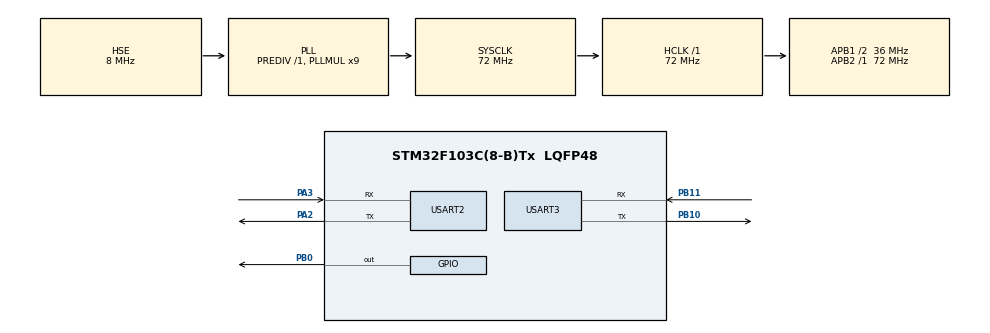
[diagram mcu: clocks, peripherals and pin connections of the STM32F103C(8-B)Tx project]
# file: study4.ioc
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FREERTOS.Tasks01=motorcontrol,40,512,Motorcontrol,Default,NULL,Dynamic,NULL,NULL;motorfeedback,24,512,Motorfeedback,Default,NULL,Dynamic,NULL,NULL
FREERTOS.configTOTAL_HEAP_SIZE=10240
Mcu.Family=STM32F1
Mcu.Name=STM32F103C(8-B)Tx
Mcu.Package=LQFP48
NVIC.PriorityGroup=NVIC_PRIORITYGROUP_4
NVIC.TIM3_IRQn=true\:15\:0\:false\:false\:true\:false\:false\:true\:true
NVIC.TimeBase=TIM3_IRQn
NVIC.TimeBaseIP=TIM3
NVIC.USART2_IRQn=true\:5\:0\:false\:false\:true\:true\:true\:true\:true
NVIC.USART3_IRQn=false\:5\:0\:false\:false\:true\:true\:false\:true\:true
PA13.Mode=Serial_Wire
PA13.Signal=SYS_JTMS-SWDIO
PA14.Mode=Serial_Wire
PA14.Signal=SYS_JTCK-SWCLK
PA2.Mode=Asynchronous
PA2.Signal=USART2_TX
PA3.Mode=Asynchronous
PA3.Signal=USART2_RX
PB0.Signal=GPIO_Output
PB10.Mode=Asynchronous
PB10.Signal=USART3_TX
PB11.Mode=Asynchronous
PB11.Signal=USART3_RX
PD0-OSC_IN.Mode=HSE-External-Oscillator
PD0-OSC_IN.Signal=RCC_OSC_IN
PD1-OSC_OUT.Mode=HSE-External-Oscillator
PD1-OSC_OUT.Signal=RCC_OSC_OUT
ProjectManager.HeapSize=0x200
ProjectManager.StackSize=0x400
ProjectManager.TargetToolchain=CMake
RCC.AHBFreq_Value=72000000
RCC.APB1CLKDivider=RCC_HCLK_DIV2
RCC.APB1Freq_Value=36000000
RCC.APB1TimFreq_Value=72000000
RCC.APB2Freq_Value=72000000
RCC.APB2TimFreq_Value=72000000
RCC.HCLKFreq_Value=72000000
RCC.PLLMUL=RCC_PLL_MUL9
RCC.PLLSourceVirtual=RCC_PLLSOURCE_HSE
RCC.SYSCLKFreq_VALUE=72000000
RCC.SYSCLKSource=RCC_SYSCLKSOURCE_PLLCLK
RCC.USBFreq_Value=72000000
USART2.VirtualMode=VM_ASYNC
USART3.VirtualMode=VM_ASYNC
VP_FREERTOS_VS_CMSIS_V2.Mode=CMSIS_V2
VP_SYS_VS_tim3.Mode=TIM3
board=custom

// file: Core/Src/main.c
/* USER CODE BEGIN Header */
/**
  ******************************************************************************
  * @file           : main.c
  * @brief          : Main program body
  ******************************************************************************
  * @attention
  *
  * Copyright (c) 2026 STMicroelectronics.
  * All rights reserved.
  *
  * This software is licensed under terms that can be found in the LICENSE file
  * in the root directory of this software component.
  * If no LICENSE file comes with this software, it is provided AS-IS.
  *
  ******************************************************************************
  */
/* USER CODE END Header */
#include "main.h"
#include "cmsis_os.h"
#include "usart.h"
#include "gpio.h"

void SystemClock_Config(void);
void MX_FREERTOS_Init(void);

/* USER CODE BEGIN 0 */
volatile uint8_t g_uart2_flag = 0;
volatile uint8_t g_uart2_data = 0;
/* USER CODE END 0 */

int main(void)
{

  /* MCU Configuration--------------------------------------------------------*/

  /* Reset of all peripherals, Initializes the Flash interface and the Systick. */
  HAL_Init();

  /* Configure the system clock */
  SystemClock_Config();

  /* Initialize all configured peripherals */
  MX_GPIO_Init();
  MX_USART3_UART_Init();
  MX_USART2_UART_Init();

  /* Init scheduler */
  osKernelInitialize();  /* Call init function for freertos objects (in cmsis_os2.c) */
  MX_FREERTOS_Init();

  /* Start scheduler */
  osKernelStart();

  /* We should never get here as control is now taken by the scheduler */

  /* Infinite loop */
  while (1)
  {

  }
}

void SystemClock_Config(void)
{
  RCC_OscInitTypeDef RCC_OscInitStruct = {0};
  RCC_ClkInitTypeDef RCC_ClkInitStruct = {0};

  /** Initializes the RCC Oscillators according to the specified parameters
  * in the RCC_OscInitTypeDef structure.
  */
  RCC_OscInitStruct.OscillatorType = RCC_OSCILLATORTYPE_HSE;
  RCC_OscInitStruct.HSEState = RCC_HSE_ON;
  RCC_OscInitStruct.HSEPredivValue = RCC_HSE_PREDIV_DIV1;
  RCC_OscInitStruct.HSIState = RCC_HSI_ON;
  RCC_OscInitStruct.PLL.PLLState = RCC_PLL_ON;
  RCC_OscInitStruct.PLL.PLLSource = RCC_PLLSOURCE_HSE;
  RCC_OscInitStruct.PLL.PLLMUL = RCC_PLL_MUL9;
  if (HAL_RCC_OscConfig(&RCC_OscInitStruct) != HAL_OK)
  {
    Error_Handler();
  }

  /** Initializes the CPU, AHB and APB buses clocks
  */
  RCC_ClkInitStruct.ClockType = RCC_CLOCKTYPE_HCLK|RCC_CLOCKTYPE_SYSCLK
                              |RCC_CLOCKTYPE_PCLK1|RCC_CLOCKTYPE_PCLK2;
  RCC_ClkInitStruct.SYSCLKSource = RCC_SYSCLKSOURCE_PLLCLK;
  RCC_ClkInitStruct.AHBCLKDivider = RCC_SYSCLK_DIV1;
  RCC_ClkInitStruct.APB1CLKDivider = RCC_HCLK_DIV2;
  RCC_ClkInitStruct.APB2CLKDivider = RCC_HCLK_DIV1;

  if (HAL_RCC_ClockConfig(&RCC_ClkInitStruct, FLASH_LATENCY_2) != HAL_OK)
  {
    Error_Handler();
  }
}

void HAL_TIM_PeriodElapsedCallback(TIM_HandleTypeDef *htim)
{
  if (htim->Instance == TIM3)
  {
    HAL_IncTick();
  }
}

void Error_Handler(void)
{
  __disable_irq();
  while (1)
  {
  }
}

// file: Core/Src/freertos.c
/* USER CODE BEGIN Header */
/**
  ******************************************************************************
  * File Name          : freertos.c
  * Description        : Code for freertos applications
  ******************************************************************************
  * @attention
  *
  * Copyright (c) 2026 STMicroelectronics.
  * All rights reserved.
  *
  * This software is licensed under terms that can be found in the LICENSE file
  * in the root directory of this software component.
  * If no LICENSE file comes with this software, it is provided AS-IS.
  *
  ******************************************************************************
  */
/* USER CODE END Header */

#include "FreeRTOS.h"
#include "task.h"
#include "main.h"
#include "cmsis_os.h"

/* USER CODE BEGIN Includes */
#include "zdt42.h"
#include "usart.h"
#include <limits.h>
#include <stdio.h>
#include <string.h>
/* USER CODE END Includes */

/* USER CODE BEGIN Variables */
static osMutexId_t motorUartMutex;
/* USER CODE END Variables */
/* Definitions for motorcontrol */
osThreadId_t motorcontrolHandle;
const osThreadAttr_t motorcontrol_attributes = {
  .name = "motorcontrol",
  .stack_size = 512 * 4,
  .priority = (osPriority_t) osPriorityHigh,
};
/* Definitions for motorfeedback */
osThreadId_t motorfeedbackHandle;
const osThreadAttr_t motorfeedback_attributes = {
  .name = "motorfeedback",
  .stack_size = 512 * 4,
  .priority = (osPriority_t) osPriorityNormal,
};

void Motorcontrol(void *argument);
void Motorfeedback(void *argument);

static void ExecuteMotorCommand(char *command);

void MX_FREERTOS_Init(void); /* (MISRA C 2004 rule 8.1) */

void MX_FREERTOS_Init(void) {

  /* USER CODE BEGIN RTOS_MUTEX */
  motorUartMutex = osMutexNew(NULL);
  if (motorUartMutex == NULL)
  {
    Error_Handler();
  }
  /* USER CODE END RTOS_MUTEX */

  /* Create the thread(s) */
  /* creation of motorcontrol */
  motorcontrolHandle = osThreadNew(Motorcontrol, NULL, &motorcontrol_attributes);
  if (motorcontrolHandle == NULL)
  {
    Error_Handler();
  }

  /* creation of motorfeedback */
  motorfeedbackHandle = osThreadNew(Motorfeedback, NULL, &motorfeedback_attributes);
  if (motorfeedbackHandle == NULL)
  {
    Error_Handler();
  }

}

void Motorcontrol(void *argument)
{
  char cmd_buf[48];
  uint8_t idx = 0U;
  uint8_t dropping_line = 0U;
  uint8_t received_byte;

  (void)argument;
  ZDT42_Init();
  if (HAL_UART_Receive_IT(&huart2, (uint8_t *)&g_uart2_data, 1U) != HAL_OK)
  {
    Error_Handler();
  }
  if (osMutexAcquire(motorUartMutex, osWaitForever) != osOK)
  {
    Error_Handler();
  }
  ZDT42_Enable(1, 1);
  if (osMutexRelease(motorUartMutex) != osOK)
  {
    Error_Handler();
  }

  for(;;)
  {
    if (USART2_TakeRxOverflow() != 0U)
    {
      idx = 0U;
      dropping_line = 1U;
      memset(cmd_buf, 0, sizeof(cmd_buf));
    }

    while (USART2_ReadByte(&received_byte) != 0U)
    {
      if (received_byte == '\r' || received_byte == '\n')
      {
        cmd_buf[idx] = '\0';
        ExecuteMotorCommand(cmd_buf);
        idx = 0U;
        memset(cmd_buf, 0, sizeof(cmd_buf));
        dropping_line = 0U;
      }
      else if (dropping_line == 0U)
      {
        if (idx < (sizeof(cmd_buf) - 1U))
        {
          cmd_buf[idx++] = (char)received_byte;
          if (idx >= (sizeof(cmd_buf) - 1U))
          {
            idx = 0U;
            dropping_line = 1U;
            memset(cmd_buf, 0, sizeof(cmd_buf));
          }
        }
        else
        {
          idx = 0U;
          dropping_line = 1U;
          memset(cmd_buf, 0, sizeof(cmd_buf));
        }
      }
    }
    osDelay(1U);
  }
}

static void ExecuteMotorCommand(char *command)
{
  char *start = command;
  size_t length;
  int value;
  char extra;
  int parsed;
  enum
  {
    MOTOR_COMMAND_NONE,
    MOTOR_COMMAND_SPEED,
    MOTOR_COMMAND_RELATIVE,
    MOTOR_COMMAND_ABSOLUTE,
    MOTOR_COMMAND_ON,
    MOTOR_COMMAND_OFF,
    MOTOR_COMMAND_STOP
  } motor_command = MOTOR_COMMAND_NONE;

  while (*start == ' ' || *start == '\t')
  {
    start++;
  }
  length = strlen(start);
  while (length > 0U &&
         (start[length - 1U] == ' ' || start[length - 1U] == '\t'))
  {
    start[--length] = '\0';
  }

  parsed = sscanf(start, "speed:%d %c", &value, &extra);
  if (parsed != 1)
  {
    parsed = sscanf(start, "speed %d %c", &value, &extra);
  }
  if (parsed == 1 && value >= INT16_MIN && value <= INT16_MAX)
  {
    motor_command = MOTOR_COMMAND_SPEED;
  }
  else
  {
    parsed = sscanf(start, "rel:%d %c", &value, &extra);
    if (parsed != 1)
    {
      parsed = sscanf(start, "rel %d %c", &value, &extra);
    }
    if (parsed == 1)
    {
      motor_command = MOTOR_COMMAND_RELATIVE;
    }
    else
    {
      parsed = sscanf(start, "abs:%d %c", &value, &extra);
      if (parsed != 1)
      {
        parsed = sscanf(start, "abs %d %c", &value, &extra);
      }
      if (parsed == 1)
      {
        motor_command = MOTOR_COMMAND_ABSOLUTE;
      }
    }
  }

  if (motor_command == MOTOR_COMMAND_NONE)
  {
    if (strcmp(start, "on") == 0)
    {
      motor_command = MOTOR_COMMAND_ON;
    }
    else if (strcmp(start, "off") == 0)
    {
      motor_command = MOTOR_COMMAND_OFF;
    }
    else if (strcmp(start, "stop") == 0)
    {
      motor_command = MOTOR_COMMAND_STOP;
    }
  }

  if (motor_command == MOTOR_COMMAND_NONE)
  {
    return;
  }

  if (osMutexAcquire(motorUartMutex, osWaitForever) != osOK)
  {
    Error_Handler();
  }

  switch (motor_command)
  {
    case MOTOR_COMMAND_SPEED:
      ZDT42_SetSpeed(1, (int16_t)value, 1000);
      break;
    case MOTOR_COMMAND_RELATIVE:
      ZDT42_MoveRelative(1, (float)value, 500, 10);
      break;
    case MOTOR_COMMAND_ABSOLUTE:
      ZDT42_MoveAbsolute(1, (float)value, 500, 10);
      break;
    case MOTOR_COMMAND_ON:
      ZDT42_Enable(1, 1);
      break;
    case MOTOR_COMMAND_OFF:
      ZDT42_Enable(1, 0);
      break;
    case MOTOR_COMMAND_STOP:
      ZDT42_Stop(1);
      break;
    default:
      break;
  }

  if (osMutexRelease(motorUartMutex) != osOK)
  {
    Error_Handler();
  }

  if (HAL_UART_Transmit(&huart2, (uint8_t *)"CMD_OK\r\n",
                        sizeof("CMD_OK\r\n") - 1U, 100U) != HAL_OK)
  {
    Error_Handler();
  }
}

void Motorfeedback(void *argument)
{
  char tx_buf[32];
  uint32_t wake_tick = osKernelGetTickCount();

  (void)argument;

  for (;;)
  {
    int16_t current_speed;
    float current_pos;
    int len;

    if (osMutexAcquire(motorUartMutex, osWaitForever) != osOK)
    {
      Error_Handler();
    }
    current_speed = ZDT42_ReadSpeed(1);
    if (osMutexRelease(motorUartMutex) != osOK)
    {
      Error_Handler();
    }

    osDelay(5U);

    if (osMutexAcquire(motorUartMutex, osWaitForever) != osOK)
    {
      Error_Handler();
    }
    current_pos = ZDT42_ReadPosition(1);
    if (osMutexRelease(motorUartMutex) != osOK)
    {
      Error_Handler();
    }

    if (current_pos > 360.0f || current_pos < -360.0f) {
    current_pos = 0.0f;
}

    len = sprintf(tx_buf, "%d,%d,\n", (int)current_speed,
                  (int)current_pos);
    if (HAL_UART_Transmit(&huart2, (uint8_t *)tx_buf, (uint16_t)len,
                          100U) != HAL_OK)
    {
      Error_Handler();
    }

    wake_tick += pdMS_TO_TICKS(50U);
    (void)osDelayUntil(wake_tick);
  }
}
